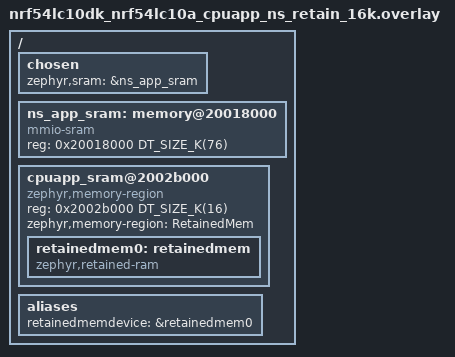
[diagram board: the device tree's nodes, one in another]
/ {
	chosen {
		zephyr,sram = &ns_app_sram;
	};

	ns_app_sram: memory@20018000 {
		compatible = "mmio-sram";
		reg = <0x20018000 DT_SIZE_K(76)>;
	};

	cpuapp_sram@2002b000 {
		compatible = "zephyr,memory-region", "mmio-sram";
		reg = <0x2002b000 DT_SIZE_K(16)>;
		zephyr,memory-region = "RetainedMem";
		status = "okay";

		retainedmem0: retainedmem {
			compatible = "zephyr,retained-ram";
			status = "okay";
		};
	};

	aliases {
		retainedmemdevice = &retainedmem0;
	};
};
